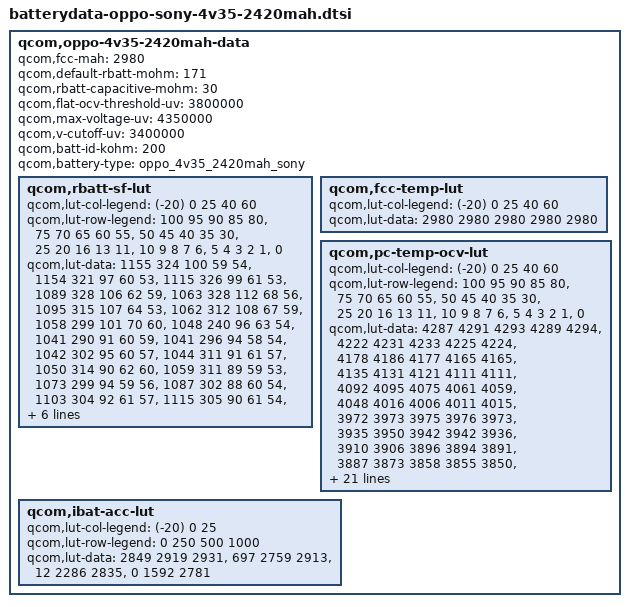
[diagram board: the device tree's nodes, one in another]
/* Copyright (c) 2013, The Linux Foundation. All rights reserved.
 *
 * This program is free software; you can redistribute it and/or modify
 * it under the terms of the GNU General Public License version 2 and
 * only version 2 as published by the Free Software Foundation.
 *
 * This program is distributed in the hope that it will be useful,
 * but WITHOUT ANY WARRANTY; without even the implied warranty of
 * MERCHANTABILITY or FITNESS FOR A PARTICULAR PURPOSE.  See the
 * GNU General Public License for more details.
 */

qcom,oppo-4v35-2420mah-data {
	qcom,fcc-mah = <2980>;
	qcom,default-rbatt-mohm = <171>;//25 deg, 100% 
	qcom,rbatt-capacitive-mohm = <30>;
	qcom,flat-ocv-threshold-uv = <3800000>;
	qcom,max-voltage-uv = <4350000>;
	qcom,v-cutoff-uv = <3400000>;
	//qcom,chg-term-ua = <100000>;
	qcom,batt-id-kohm = <200>;
	qcom,battery-type = "oppo_4v35_2420mah_sony";	//ATL cell

	qcom,rbatt-sf-lut {
		qcom,lut-col-legend = <(-20) 0 25 40 60>;
		qcom,lut-row-legend = <100 95 90 85 80>,
				<75 70 65 60 55>,
				<50 45 40 35 30>,
				<25 20 16 13 11>,
				<10 9 8 7 6>,
				<5 4 3 2 1>,
				<0>;
		qcom,lut-data = 
				<1155	324	100	59	54>,
				<1154	321	97	60	53>,
				<1115	326	99	61	53>,
				<1089	328	106	62	59>,
				<1063	328	112	68	56>,
				<1095	315	107	64	53>,
				<1062	312	108	67	59>,
				<1058	299	101	70	60>,
				<1048	240	96	63	54>,
				<1041	290	91	60	59>,
				<1041	296	94	58	54>,
				<1042	302	95	60	57>,
				<1044	311	91	61	57>,
				<1050	314	90	62	60>,
				<1059	311	89	59	53>,
				<1073	299	94	59	56>,
				<1087	302	88	60	54>,
				<1103	304	92	61	57>,
				<1115	305	90	61	54>,
				<1125	323	85	60	54>,
				<1076	327	84	61	60>,
				<1080	334	84	62	57>,
				<1086	340	86	64	57>,
				<1091	339	89	65	60>,
				<1101	368	85	64	56>,
				<1105	378	84	63	56>,
				<1248	400	88	65	62>,
				<1315	411	92	66	59>,
				<1456	572	99	70	63>,
				<1693	746	104	75	72>,
				<2053	988	399	315	315>;
		};

	qcom,fcc-temp-lut {
		qcom,lut-col-legend = <(-20) 0 25 40 60>;
		qcom,lut-data = <2980 2980 2980 2980 2980>;
	};
				
	qcom,pc-temp-ocv-lut {
		qcom,lut-col-legend = <(-20) 0 25 40 60>;
		qcom,lut-row-legend = <100 95 90 85 80>,
				<75 70 65 60 55>,
				<50 45 40 35 30>,
				<25 20 16 13 11>,
				<10 9 8 7 6>,
				<5 4 3 2 1>,
				<0>;
		//qcom,lut-data = <4332 4333 4322 4327 4313>,
		//		<4249 4267 4257 4262 4248>,
		qcom,lut-data = 
				<4287	4291	4293	4289	4294>,
				<4222	4231	4233	4225	4224>,
				<4178	4186	4177	4165	4165>,//90
				<4135	4131	4121	4111	4111>,
				<4092	4095	4075	4061	4059>,
				<4048	4016	4006	4011	4015>,//75
				<3972	3973	3975	3976	3973>,
				<3935	3950	3942	3942	3936>,
				<3910	3906	3896	3894	3891>,//60
				<3887	3873	3858	3855	3850>,
				<3863	3848	3835	3829	3827>,
				<3842	3830	3815	3811	3804>,//45
				<3824	3814	3800	3795	3790>,
				<3809	3804	3787	3783	3773>,
				<3796	3795	3773	3763	3752>,//30
				<3788	3786	3756	3745	3726>,
				<3782	3772	3738	3732	3708>,
				<3777	3754	3719	3708	3687>,//16
				<3772	3736	3699	3690	3667>,
				<3768	3723	3691	3685	3664>,
				<3786	3721	3690	3683	3666>,//10
				<3782	3719	3689	3682	3663>,
				<3778	3717	3687	3680	3659>,
				<3774	3716	3685	3678	3658>,//7
				<3767	3711	3669	3664	3640>,
				<3764	3705	3648	3644	3617>,
				<3701	3673	3589	3583	3559>,//4
				<3657	3641	3551	3544	3522>,
				<3603	3505	3444	3435	3423>,
				<3364	3355	3363	3352	3349>,
				<3000	3083	3000	3000	3040>;
		};

	qcom,ibat-acc-lut {
		qcom,lut-col-legend = <(-20) 0 25>;
		qcom,lut-row-legend = <0 250 500 1000>;
		qcom,lut-data = 
				<2849 2919 2931>,
				<697 2759 2913>,
				<12 2286 2835>,
				<0 1592 2781>;
	};

};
